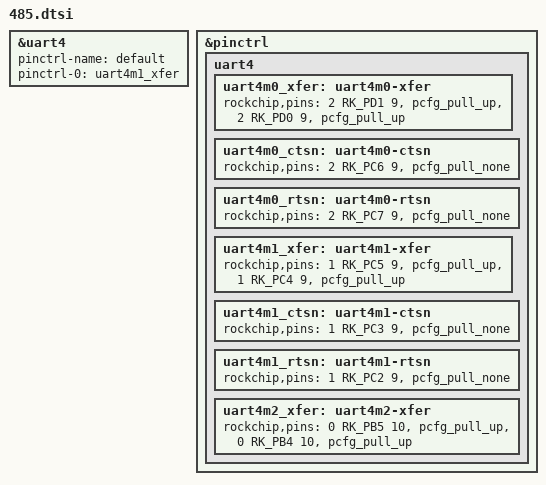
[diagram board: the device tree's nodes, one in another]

&uart4 {
	status = "okay";
	pinctrl-name = "default";
	pinctrl-0 = <&uart4m1_xfer>;
};

&pinctrl {
	uart4 {
		/omit-if-no-ref/
		uart4m0_xfer: uart4m0-xfer {
			rockchip,pins =
				/* uart4_rx_m0 */
				<2 RK_PD1 9 &pcfg_pull_up>,
				/* uart4_tx_m0 */
				<2 RK_PD0 9 &pcfg_pull_up>;
		};

		/omit-if-no-ref/
		uart4m0_ctsn: uart4m0-ctsn {
			rockchip,pins =
				/* uart4m0_ctsn */
				<2 RK_PC6 9 &pcfg_pull_none>;
		};
		/omit-if-no-ref/
		uart4m0_rtsn: uart4m0-rtsn {
			rockchip,pins =
				/* uart4m0_rtsn */
				<2 RK_PC7 9 &pcfg_pull_none>;
		};

		/omit-if-no-ref/
		uart4m1_xfer: uart4m1-xfer {
			rockchip,pins =
				/* uart4_rx_m1 */
				<1 RK_PC5 9 &pcfg_pull_up>,
				/* uart4_tx_m1 */
				<1 RK_PC4 9 &pcfg_pull_up>;
		};

		/omit-if-no-ref/
		uart4m1_ctsn: uart4m1-ctsn {
			rockchip,pins =
				/* uart4m1_ctsn */
				<1 RK_PC3 9 &pcfg_pull_none>;
		};
		/omit-if-no-ref/
		uart4m1_rtsn: uart4m1-rtsn {
			rockchip,pins =
				/* uart4m1_rtsn */
				<1 RK_PC2 9 &pcfg_pull_none>;
		};

		/omit-if-no-ref/
		uart4m2_xfer: uart4m2-xfer {
			rockchip,pins =
				/* uart4_rx_m2 */
				<0 RK_PB5 10 &pcfg_pull_up>,
				/* uart4_tx_m2 */
				<0 RK_PB4 10 &pcfg_pull_up>;
		};
	};
};
